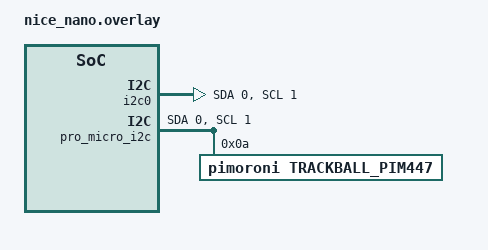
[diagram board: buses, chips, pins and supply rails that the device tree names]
&i2c0 {
	compatible = "nordic,nrf-twi";
	sda-pin = <0>;
	scl-pin = <1>;
};


&pro_micro_i2c {
    status = "okay";
	sda-pin = <0>;
	scl-pin = <1>;

    trackball_pim447@a {
        compatible = "pimoroni,trackball_pim447";
        reg = <0xa>;
        label = "TRACKBALL_PIM447";
    };
};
